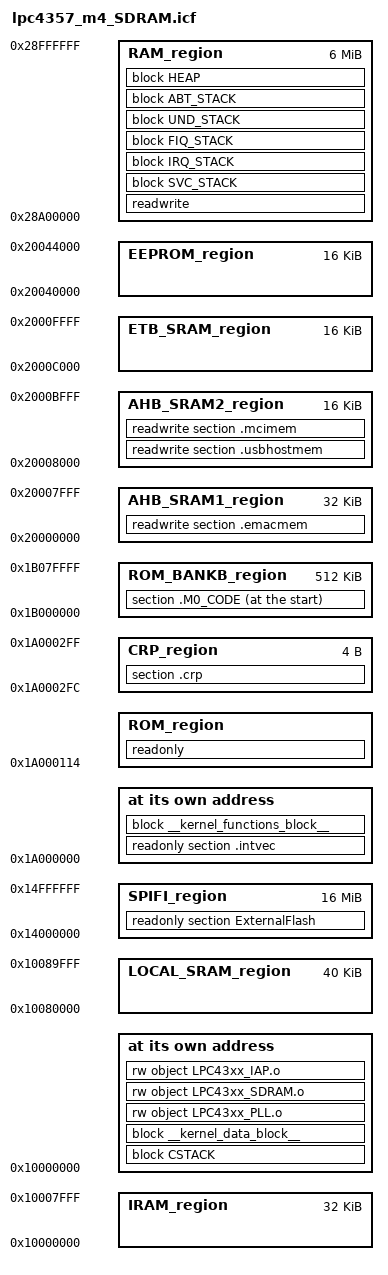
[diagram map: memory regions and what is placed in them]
/*###ICF### Section handled by ICF editor, don't touch! ****/
/*-Editor annotation file-*/
/* IcfEditorFile="$TOOLKIT_DIR$\config\ide\IcfEditor\cortex_v1_0.xml" */
/*-Specials-*/
define symbol __ICFEDIT_intvec_start__ = 0x1A000000;

/*-Memory Regions-*/
define symbol __ICFEDIT_region_ROM_start__ = 0x1A000114;
define symbol __ICFEDIT_region_ROM_end__   = 0x1A07FFFF;
define symbol __ICFEDIT_region_RAM_start__ = 0x28A00000;
define symbol __ICFEDIT_region_RAM_end__   = 0x28FFFFFF;

/*-Sizes-*/
define symbol __ICFEDIT_size_cstack__   = 0x400;
define symbol __ICFEDIT_size_svcstack__ = 0x10;
define symbol __ICFEDIT_size_irqstack__ = 0x100;
define symbol __ICFEDIT_size_fiqstack__ = 0x100;
define symbol __ICFEDIT_size_undstack__ = 0x10;
define symbol __ICFEDIT_size_abtstack__ = 0x10;
define symbol __ICFEDIT_size_heap__     = 5000000;
/**** End of ICF editor section. ###ICF###*/

define symbol __size_vectors__              = 0xE8;

/*-- uEZ Defines: -----------------------------------------------------------*/
/* USe the SRAM for the system stack and the kernel data. */
define symbol IRAM_start        = 0x10000000;
define symbol IRAM_end          = 0x10007FFF;


/********** Flash BankB Region **********/
define symbol __ICFEDIT_region_ROM_BANKB_start__ = 0x1B000000;
define symbol __ICFEDIT_region_ROM_BANKB_end__   = 0x1B07FFFF;

/********** Local SRAM Region **********/
define symbol LOCAL_SRAM_start__    = 0x10080000;
define symbol LOCAL_SRAM_end__      = 0x10089FFF;

/********** AHB SRAM Region 1 **********/
define symbol AHB_SRAM1_start__     = 0x20000000;
define symbol AHB_SRAM1_end__       = 0x20007FFF;

/********** AHB SRAM Region 2 **********/
define symbol AHB_SRAM2_start__     = 0x20008000;
define symbol AHB_SRAM2_end__       = 0x2000BFFF;

/********* ETB/AHB SRAM Region *********/
define symbol ETB_SRAM_start__      = 0x2000C000;
define symbol ETB_SRAM_end__        = 0x2000FFFF;

/********* CRP REGION *********/
define symbol __CRP_start__   = 0x1A0002FC;
define symbol __CRP_end__     = 0x1A0002FF;

define symbol __SPIFI_start   = 0x14000000; 
define symbol __SPIFI_end     = 0x14FFFFFF;

/********* EEPROM REGION *********/
define symbol __EE_start__   = 0x20040000;
define symbol __EE_end__     = 0x20044000;

define memory mem with size = 4G;
define region ROM_region           = mem:[from __ICFEDIT_region_ROM_start__   to __ICFEDIT_region_ROM_end__] - mem:[from  __CRP_start__ to __CRP_end__];
define region ROM_BANKB_region     = mem:[from __ICFEDIT_region_ROM_BANKB_start__ to __ICFEDIT_region_ROM_BANKB_end__];
define region IRAM_region          = mem:[from IRAM_start to IRAM_end];
define region RAM_region           = mem:[from __ICFEDIT_region_RAM_start__   to __ICFEDIT_region_RAM_end__];
define region LOCAL_SRAM_region    = mem:[from LOCAL_SRAM_start__             to LOCAL_SRAM_end__];
define region AHB_SRAM1_region     = mem:[from AHB_SRAM1_start__              to AHB_SRAM1_end__];
define region AHB_SRAM2_region     = mem:[from AHB_SRAM2_start__              to AHB_SRAM2_end__];
define region ETB_SRAM_region      = mem:[from ETB_SRAM_start__               to ETB_SRAM_end__];
define region CRP_region           = mem:[from  __CRP_start__ to __CRP_end__];
define region SPIFI_region         = mem:[from  __SPIFI_start to __SPIFI_end];
define region EEPROM_region        = mem:[from  __EE_start__ to __EE_end__];

/*-- Blocks: ----------------------------------------------------------------*/
define block CSTACK    with alignment = 8, size = __ICFEDIT_size_cstack__   { };
define block SVC_STACK with alignment = 8, size = __ICFEDIT_size_svcstack__ { };
define block IRQ_STACK with alignment = 8, size = __ICFEDIT_size_irqstack__ { };
define block FIQ_STACK with alignment = 8, size = __ICFEDIT_size_fiqstack__ { };
define block UND_STACK with alignment = 8, size = __ICFEDIT_size_undstack__ { };
define block ABT_STACK with alignment = 8, size = __ICFEDIT_size_abtstack__ { };
define block HEAP      with alignment = 8, size = __ICFEDIT_size_heap__     { };

/*-- Placment Commands (General): -------------------------------------------*/
initialize by copy { readwrite };
do not initialize  { section .noinit };

/* Define a block for the kernel's functions.  - __size_vectors__ because the 
first part of the 8K is taken by the interrupt vectors. */
define block __kernel_functions_block__ with alignment = 8, 
    size = 0x2000 - __size_vectors__ { section __kernel_functions__ };

/* Place the interrupt vectors at the required address, followed by the kernel's
functions. */
place at address mem:__ICFEDIT_intvec_start__ { 
    readonly section .intvec, 
    block __kernel_functions_block__ 
};

/* Define a block for the kernel's data. */
define block __kernel_data_block__ with alignment = 0x400, size = 0x400 { section __kernel_data__ };

/* Place the main stack at the start of IRAM, followed by the kernel's data. */
place at address mem:IRAM_start  { 
    block CSTACK, 
    block __kernel_data_block__, 
    rw object LPC43xx_PLL.o,
    rw object LPC43xx_SDRAM.o,
    rw object LPC43xx_IAP.o
};

place in ROM_region   { readonly };

place in RAM_region { 
    readwrite,
    block SVC_STACK, 
    block IRQ_STACK, 
    block FIQ_STACK,
    block UND_STACK, 
    block ABT_STACK, 
    block HEAP
};

place in SPIFI_region { readonly section ExternalFlash 

};

place in AHB_SRAM1_region {
    readwrite section .emacmem,
};

place in AHB_SRAM2_region {
    readwrite section .usbhostmem,
    readwrite section .mcimem,
};

place at start of ROM_BANKB_region  { section .M0_CODE };

place in CRP_region              { section .crp };

/*-- Exports: ---------------------------------------------------------------*/
/* Export symbols required by c code. */
export symbol __ICFEDIT_intvec_start__;
export symbol __ICFEDIT_size_cstack__;
export symbol __ICFEDIT_region_ROM_start__;
export symbol __ICFEDIT_region_ROM_end__;
